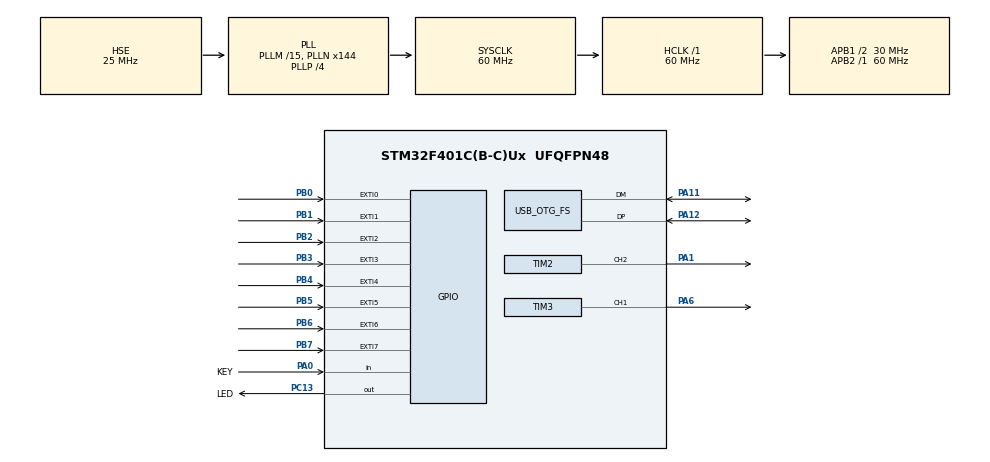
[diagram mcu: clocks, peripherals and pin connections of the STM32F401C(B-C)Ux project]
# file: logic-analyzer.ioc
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Dma.Request0=TIM1_UP
Dma.TIM1_UP.0.Direction=DMA_PERIPH_TO_MEMORY
Dma.TIM1_UP.0.FIFOMode=DMA_FIFOMODE_DISABLE
Dma.TIM1_UP.0.Instance=DMA2_Stream5
Dma.TIM1_UP.0.MemDataAlignment=DMA_MDATAALIGN_BYTE
Dma.TIM1_UP.0.MemInc=DMA_MINC_ENABLE
Dma.TIM1_UP.0.Mode=DMA_CIRCULAR
Dma.TIM1_UP.0.PeriphDataAlignment=DMA_PDATAALIGN_BYTE
Dma.TIM1_UP.0.PeriphInc=DMA_PINC_DISABLE
Dma.TIM1_UP.0.Priority=DMA_PRIORITY_VERY_HIGH
Mcu.Family=STM32F4
Mcu.Name=STM32F401C(B-C)Ux
Mcu.Package=UFQFPN48
Mcu.UserConstants=DELAY_PRESCALER,3
NVIC.EXTI0_IRQn=true\:0\:0\:false\:false\:true\:true\:true\:true
NVIC.EXTI1_IRQn=true\:0\:0\:false\:false\:true\:true\:true\:true
NVIC.EXTI2_IRQn=true\:0\:0\:false\:false\:true\:true\:true\:true
NVIC.EXTI3_IRQn=true\:0\:0\:false\:false\:true\:true\:true\:true
NVIC.EXTI4_IRQn=true\:0\:0\:false\:false\:true\:true\:true\:true
NVIC.EXTI9_5_IRQn=true\:0\:0\:false\:false\:true\:true\:true\:true
NVIC.OTG_FS_IRQn=true\:1\:0\:true\:false\:true\:false\:true\:true
NVIC.PriorityGroup=NVIC_PRIORITYGROUP_4
NVIC.TIM3_IRQn=true\:1\:0\:true\:false\:false\:true\:false\:true
PA0-WKUP.GPIO_Label=KEY
PA0-WKUP.Signal=GPIO_Input
PA1.Signal=S_TIM2_CH2
PA11.Mode=Device_Only
PA11.Signal=USB_OTG_FS_DM
PA12.Mode=Device_Only
PA12.Signal=USB_OTG_FS_DP
PA13.Mode=Serial_Wire
PA13.Signal=SYS_JTMS-SWDIO
PA14.Mode=Serial_Wire
PA14.Signal=SYS_JTCK-SWCLK
PA6.Signal=S_TIM3_CH1
PB0.Signal=GPXTI0
PB1.Signal=GPXTI1
PB2.Signal=GPXTI2
PB3.Signal=GPXTI3
PB4.Signal=GPXTI4
PB5.Signal=GPXTI5
PB6.Signal=GPXTI6
PB7.Signal=GPXTI7
PC13-ANTI_TAMP.GPIO_Label=LED
PC13-ANTI_TAMP.Signal=GPIO_Output
PH0\ -\ OSC_IN.Mode=HSE-External-Oscillator
PH0\ -\ OSC_IN.Signal=RCC_OSC_IN
PH1\ -\ OSC_OUT.Mode=HSE-External-Oscillator
PH1\ -\ OSC_OUT.Signal=RCC_OSC_OUT
ProjectManager.HeapSize=0x0
ProjectManager.StackSize=0x400
ProjectManager.TargetToolchain=CMake
RCC.48MHZClocksFreq_Value=48000000
RCC.AHBFreq_Value=60000000
RCC.APB1CLKDivider=RCC_HCLK_DIV2
RCC.APB1Freq_Value=30000000
RCC.APB1TimFreq_Value=60000000
RCC.APB2Freq_Value=60000000
RCC.APB2TimFreq_Value=60000000
RCC.CortexFreq_Value=60000000
RCC.HCLKFreq_Value=60000000
RCC.HSE_VALUE=25000000
RCC.HSI_VALUE=16000000
RCC.LSE_VALUE=32768
RCC.PLLM=15
RCC.PLLN=144
RCC.PLLP=RCC_PLLP_DIV4
RCC.PLLQ=5
RCC.SYSCLKFreq_VALUE=60000000
RCC.SYSCLKSource=RCC_SYSCLKSOURCE_PLLCLK
RCC.VCOOutputFreq_Value=240000000
SH.S_TIM2_CH2.0=TIM2_CH2,PWM Generation2 CH2
SH.S_TIM3_CH1.0=TIM3_CH1,PWM Generation1 CH1
TIM1.Period=4
TIM1.TIM_MasterOutputTrigger=TIM_TRGO_UPDATE
TIM1.TIM_MasterSlaveMode=TIM_MASTERSLAVEMODE_DISABLE
TIM2.Channel-PWM\ Generation2\ CH2=TIM_CHANNEL_2
TIM2.Period=5999
TIM2.Pulse-PWM\ Generation2\ CH2=3000
TIM3.Channel-PWM\ Generation1\ CH1=TIM_CHANNEL_1
TIM3.OC1Preload_PWM=DISABLE
TIM3.Period=0
TIM3.Prescaler=DELAY_PRESCALER
TIM3.TIM_MasterOutputTrigger=TIM_TRGO_OC1REF
TIM3.TIM_MasterSlaveMode=TIM_MASTERSLAVEMODE_DISABLE
USB_DEVICE.APP_RX_DATA_SIZE=64
USB_DEVICE.APP_TX_DATA_SIZE=64
USB_DEVICE.CLASS_NAME_FS=CDC
USB_DEVICE.MANUFACTURER_STRING=Chamber6812
USB_DEVICE.USBD_SELF_POWERED=1
USB_DEVICE.VirtualMode=Cdc
USB_DEVICE.VirtualModeFS=Cdc_FS
USB_OTG_FS.Sof_enable=DISABLE
USB_OTG_FS.VirtualMode=Device_Only
VP_TIM1_VS_ClockSourceINT.Mode=Internal
VP_TIM1_VS_ClockSourceITR.Mode=TriggerSource_ITR2
VP_TIM1_VS_ControllerModeGated.Mode=Gated Mode
VP_TIM2_VS_ClockSourceINT.Mode=Internal
VP_TIM3_VS_ClockSourceITR.Mode=TriggerSource_ITR0
VP_TIM3_VS_ControllerModeClock.Mode=Clock Mode
VP_TIM3_VS_OPM.Mode=OPM_bit
VP_USB_DEVICE_VS_USB_DEVICE_CDC_FS.Mode=CDC_FS
board=custom

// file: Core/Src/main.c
/* USER CODE BEGIN Header */
/**
 ******************************************************************************
 * @file           : main.c
 * @brief          : Main program body
 ******************************************************************************
 * @attention
 *
 * Copyright (c) 2026 STMicroelectronics.
 * All rights reserved.
 *
 * This software is licensed under terms that can be found in the LICENSE file
 * in the root directory of this software component.
 * If no LICENSE file comes with this software, it is provided AS-IS.
 *
 ******************************************************************************
 */
/* USER CODE END Header */
#include "main.h"
#include "usb_device.h"

TIM_HandleTypeDef htim1;
TIM_HandleTypeDef htim2;
TIM_HandleTypeDef htim3;
DMA_HandleTypeDef hdma_tim1_up;

void SystemClock_Config(void);
static void MX_GPIO_Init(void);
static void MX_DMA_Init(void);
static void MX_TIM3_Init(void);
static void MX_TIM1_Init(void);
static void MX_TIM2_Init(void);
/* USER CODE BEGIN PFP */
extern int cpp_main();
/* USER CODE END PFP */

int main(void)
{

  /* MCU Configuration--------------------------------------------------------*/

  /* Reset of all peripherals, Initializes the Flash interface and the Systick. */
  HAL_Init();

  /* Configure the system clock */
  SystemClock_Config();

  /* Initialize all configured peripherals */
  MX_GPIO_Init();
  MX_DMA_Init();
  MX_USB_DEVICE_Init();
  MX_TIM3_Init();
  MX_TIM1_Init();
  MX_TIM2_Init();
  /* USER CODE BEGIN 2 */
  return cpp_main();
  /* USER CODE END 2 */

  /* Infinite loop */
  while (1) {

  }
}

void SystemClock_Config(void)
{
  RCC_OscInitTypeDef RCC_OscInitStruct = {0};
  RCC_ClkInitTypeDef RCC_ClkInitStruct = {0};

  /** Configure the main internal regulator output voltage
  */
  __HAL_RCC_PWR_CLK_ENABLE();
  __HAL_PWR_VOLTAGESCALING_CONFIG(PWR_REGULATOR_VOLTAGE_SCALE2);

  /** Initializes the RCC Oscillators according to the specified parameters
  * in the RCC_OscInitTypeDef structure.
  */
  RCC_OscInitStruct.OscillatorType = RCC_OSCILLATORTYPE_HSE;
  RCC_OscInitStruct.HSEState = RCC_HSE_ON;
  RCC_OscInitStruct.PLL.PLLState = RCC_PLL_ON;
  RCC_OscInitStruct.PLL.PLLSource = RCC_PLLSOURCE_HSE;
  RCC_OscInitStruct.PLL.PLLM = 15;
  RCC_OscInitStruct.PLL.PLLN = 144;
  RCC_OscInitStruct.PLL.PLLP = RCC_PLLP_DIV4;
  RCC_OscInitStruct.PLL.PLLQ = 5;
  if (HAL_RCC_OscConfig(&RCC_OscInitStruct) != HAL_OK)
  {
    Error_Handler();
  }

  /** Initializes the CPU, AHB and APB buses clocks
  */
  RCC_ClkInitStruct.ClockType = RCC_CLOCKTYPE_HCLK|RCC_CLOCKTYPE_SYSCLK
                              |RCC_CLOCKTYPE_PCLK1|RCC_CLOCKTYPE_PCLK2;
  RCC_ClkInitStruct.SYSCLKSource = RCC_SYSCLKSOURCE_PLLCLK;
  RCC_ClkInitStruct.AHBCLKDivider = RCC_SYSCLK_DIV1;
  RCC_ClkInitStruct.APB1CLKDivider = RCC_HCLK_DIV2;
  RCC_ClkInitStruct.APB2CLKDivider = RCC_HCLK_DIV1;

  if (HAL_RCC_ClockConfig(&RCC_ClkInitStruct, FLASH_LATENCY_1) != HAL_OK)
  {
    Error_Handler();
  }
}

static void MX_TIM1_Init(void)
{

  TIM_ClockConfigTypeDef sClockSourceConfig = {0};
  TIM_SlaveConfigTypeDef sSlaveConfig = {0};
  TIM_MasterConfigTypeDef sMasterConfig = {0};

  htim1.Instance = TIM1;
  htim1.Init.Prescaler = 0;
  htim1.Init.CounterMode = TIM_COUNTERMODE_UP;
  htim1.Init.Period = 4;
  htim1.Init.ClockDivision = TIM_CLOCKDIVISION_DIV1;
  htim1.Init.RepetitionCounter = 0;
  htim1.Init.AutoReloadPreload = TIM_AUTORELOAD_PRELOAD_DISABLE;
  if (HAL_TIM_Base_Init(&htim1) != HAL_OK)
  {
    Error_Handler();
  }
  sClockSourceConfig.ClockSource = TIM_CLOCKSOURCE_INTERNAL;
  if (HAL_TIM_ConfigClockSource(&htim1, &sClockSourceConfig) != HAL_OK)
  {
    Error_Handler();
  }
  sSlaveConfig.SlaveMode = TIM_SLAVEMODE_GATED;
  sSlaveConfig.InputTrigger = TIM_TS_ITR2;
  if (HAL_TIM_SlaveConfigSynchro(&htim1, &sSlaveConfig) != HAL_OK)
  {
    Error_Handler();
  }
  sMasterConfig.MasterOutputTrigger = TIM_TRGO_UPDATE;
  sMasterConfig.MasterSlaveMode = TIM_MASTERSLAVEMODE_DISABLE;
  if (HAL_TIMEx_MasterConfigSynchronization(&htim1, &sMasterConfig) != HAL_OK)
  {
    Error_Handler();
  }

}

static void MX_TIM2_Init(void)
{

  TIM_ClockConfigTypeDef sClockSourceConfig = {0};
  TIM_MasterConfigTypeDef sMasterConfig = {0};
  TIM_OC_InitTypeDef sConfigOC = {0};

  htim2.Instance = TIM2;
  htim2.Init.Prescaler = 0;
  htim2.Init.CounterMode = TIM_COUNTERMODE_UP;
  htim2.Init.Period = 6000-1;
  htim2.Init.ClockDivision = TIM_CLOCKDIVISION_DIV1;
  htim2.Init.AutoReloadPreload = TIM_AUTORELOAD_PRELOAD_DISABLE;
  if (HAL_TIM_Base_Init(&htim2) != HAL_OK)
  {
    Error_Handler();
  }
  sClockSourceConfig.ClockSource = TIM_CLOCKSOURCE_INTERNAL;
  if (HAL_TIM_ConfigClockSource(&htim2, &sClockSourceConfig) != HAL_OK)
  {
    Error_Handler();
  }
  if (HAL_TIM_PWM_Init(&htim2) != HAL_OK)
  {
    Error_Handler();
  }
  sMasterConfig.MasterOutputTrigger = TIM_TRGO_RESET;
  sMasterConfig.MasterSlaveMode = TIM_MASTERSLAVEMODE_DISABLE;
  if (HAL_TIMEx_MasterConfigSynchronization(&htim2, &sMasterConfig) != HAL_OK)
  {
    Error_Handler();
  }
  sConfigOC.OCMode = TIM_OCMODE_PWM1;
  sConfigOC.Pulse = 3000;
  sConfigOC.OCPolarity = TIM_OCPOLARITY_HIGH;
  sConfigOC.OCFastMode = TIM_OCFAST_DISABLE;
  if (HAL_TIM_PWM_ConfigChannel(&htim2, &sConfigOC, TIM_CHANNEL_2) != HAL_OK)
  {
    Error_Handler();
  }
  HAL_TIM_MspPostInit(&htim2);

}

static void MX_TIM3_Init(void)
{

  TIM_SlaveConfigTypeDef sSlaveConfig = {0};
  TIM_MasterConfigTypeDef sMasterConfig = {0};
  TIM_OC_InitTypeDef sConfigOC = {0};

  htim3.Instance = TIM3;
  htim3.Init.Prescaler = DELAY_PRESCALER;
  htim3.Init.CounterMode = TIM_COUNTERMODE_UP;
  htim3.Init.Period = 0;
  htim3.Init.ClockDivision = TIM_CLOCKDIVISION_DIV1;
  htim3.Init.AutoReloadPreload = TIM_AUTORELOAD_PRELOAD_DISABLE;
  if (HAL_TIM_Base_Init(&htim3) != HAL_OK)
  {
    Error_Handler();
  }
  if (HAL_TIM_PWM_Init(&htim3) != HAL_OK)
  {
    Error_Handler();
  }
  if (HAL_TIM_OnePulse_Init(&htim3, TIM_OPMODE_SINGLE) != HAL_OK)
  {
    Error_Handler();
  }
  sSlaveConfig.SlaveMode = TIM_SLAVEMODE_EXTERNAL1;
  sSlaveConfig.InputTrigger = TIM_TS_ITR0;
  if (HAL_TIM_SlaveConfigSynchro(&htim3, &sSlaveConfig) != HAL_OK)
  {
    Error_Handler();
  }
  sMasterConfig.MasterOutputTrigger = TIM_TRGO_OC1REF;
  sMasterConfig.MasterSlaveMode = TIM_MASTERSLAVEMODE_DISABLE;
  if (HAL_TIMEx_MasterConfigSynchronization(&htim3, &sMasterConfig) != HAL_OK)
  {
    Error_Handler();
  }
  sConfigOC.OCMode = TIM_OCMODE_PWM1;
  sConfigOC.Pulse = 0;
  sConfigOC.OCPolarity = TIM_OCPOLARITY_HIGH;
  sConfigOC.OCFastMode = TIM_OCFAST_DISABLE;
  if (HAL_TIM_PWM_ConfigChannel(&htim3, &sConfigOC, TIM_CHANNEL_1) != HAL_OK)
  {
    Error_Handler();
  }
  __HAL_TIM_DISABLE_OCxPRELOAD(&htim3, TIM_CHANNEL_1);
  HAL_TIM_MspPostInit(&htim3);

}

static void MX_DMA_Init(void)
{

  /* DMA controller clock enable */
  __HAL_RCC_DMA2_CLK_ENABLE();

}

static void MX_GPIO_Init(void)
{
  GPIO_InitTypeDef GPIO_InitStruct = {0};

  /* GPIO Ports Clock Enable */
  __HAL_RCC_GPIOC_CLK_ENABLE();
  __HAL_RCC_GPIOH_CLK_ENABLE();
  __HAL_RCC_GPIOA_CLK_ENABLE();
  __HAL_RCC_GPIOB_CLK_ENABLE();

  /*Configure GPIO pin Output Level */
  HAL_GPIO_WritePin(LED_GPIO_Port, LED_Pin, GPIO_PIN_RESET);

  /*Configure GPIO pin : LED_Pin */
  GPIO_InitStruct.Pin = LED_Pin;
  GPIO_InitStruct.Mode = GPIO_MODE_OUTPUT_PP;
  GPIO_InitStruct.Pull = GPIO_NOPULL;
  GPIO_InitStruct.Speed = GPIO_SPEED_FREQ_LOW;
  HAL_GPIO_Init(LED_GPIO_Port, &GPIO_InitStruct);

  /*Configure GPIO pins : PC14 PC15 */
  GPIO_InitStruct.Pin = GPIO_PIN_14|GPIO_PIN_15;
  GPIO_InitStruct.Mode = GPIO_MODE_ANALOG;
  GPIO_InitStruct.Pull = GPIO_NOPULL;
  HAL_GPIO_Init(GPIOC, &GPIO_InitStruct);

  /*Configure GPIO pin : KEY_Pin */
  GPIO_InitStruct.Pin = KEY_Pin;
  GPIO_InitStruct.Mode = GPIO_MODE_INPUT;
  GPIO_InitStruct.Pull = GPIO_NOPULL;
  HAL_GPIO_Init(KEY_GPIO_Port, &GPIO_InitStruct);

  /*Configure GPIO pins : PA2 PA3 PA4 PA5
                           PA7 PA8 PA9 PA10
                           PA15 */
  GPIO_InitStruct.Pin = GPIO_PIN_2|GPIO_PIN_3|GPIO_PIN_4|GPIO_PIN_5
                          |GPIO_PIN_7|GPIO_PIN_8|GPIO_PIN_9|GPIO_PIN_10
                          |GPIO_PIN_15;
  GPIO_InitStruct.Mode = GPIO_MODE_ANALOG;
  GPIO_InitStruct.Pull = GPIO_NOPULL;
  HAL_GPIO_Init(GPIOA, &GPIO_InitStruct);

  /*Configure GPIO pins : PB0 PB1 PB2 PB3
                           PB4 PB5 PB6 PB7 */
  GPIO_InitStruct.Pin = GPIO_PIN_0|GPIO_PIN_1|GPIO_PIN_2|GPIO_PIN_3
                          |GPIO_PIN_4|GPIO_PIN_5|GPIO_PIN_6|GPIO_PIN_7;
  GPIO_InitStruct.Mode = GPIO_MODE_IT_RISING;
  GPIO_InitStruct.Pull = GPIO_NOPULL;
  HAL_GPIO_Init(GPIOB, &GPIO_InitStruct);

  /*Configure GPIO pins : PB10 PB12 PB13 PB14
                           PB15 PB8 PB9 */
  GPIO_InitStruct.Pin = GPIO_PIN_10|GPIO_PIN_12|GPIO_PIN_13|GPIO_PIN_14
                          |GPIO_PIN_15|GPIO_PIN_8|GPIO_PIN_9;
  GPIO_InitStruct.Mode = GPIO_MODE_ANALOG;
  GPIO_InitStruct.Pull = GPIO_NOPULL;
  HAL_GPIO_Init(GPIOB, &GPIO_InitStruct);

  /* EXTI interrupt init*/
  HAL_NVIC_SetPriority(EXTI0_IRQn, 0, 0);
  HAL_NVIC_EnableIRQ(EXTI0_IRQn);

  HAL_NVIC_SetPriority(EXTI1_IRQn, 0, 0);
  HAL_NVIC_EnableIRQ(EXTI1_IRQn);

  HAL_NVIC_SetPriority(EXTI2_IRQn, 0, 0);
  HAL_NVIC_EnableIRQ(EXTI2_IRQn);

  HAL_NVIC_SetPriority(EXTI3_IRQn, 0, 0);
  HAL_NVIC_EnableIRQ(EXTI3_IRQn);

  HAL_NVIC_SetPriority(EXTI4_IRQn, 0, 0);
  HAL_NVIC_EnableIRQ(EXTI4_IRQn);

  HAL_NVIC_SetPriority(EXTI9_5_IRQn, 0, 0);
  HAL_NVIC_EnableIRQ(EXTI9_5_IRQn);

}

void Error_Handler(void)
{
  __disable_irq();
  while (1) {
  }
}
#ifdef USE_FULL_ASSERT
/**
  * @brief  Reports the name of the source file and the source line number
  *         where the assert_param error has occurred.
  * @param  file: pointer to the source file name
  * @param  line: assert_param error line source number
  * @retval None
  */
void assert_failed(uint8_t *file, uint32_t line)
{
  /* USER CODE BEGIN 6 */
  /* User can add his own implementation to report the file name and line
     number, ex: printf("Wrong parameters value: file %s on line %d\r\n", file,
     line) */
  /* USER CODE END 6 */
}
#endif /* USE_FULL_ASSERT */
